AUTOSAR XML (schema 00053)
package /Application
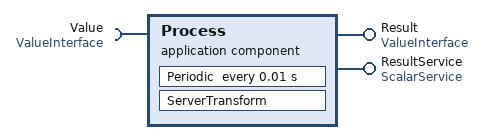
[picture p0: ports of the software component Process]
  application sw component type Process
    require port Value: nonqueued-receiver-com-spec{data-element=Value, init-value=7}, required-interface=ValueInterface
    provide port Result: nonqueued-sender-com-spec{data-element=Value, init-value=2}, provided-interface=ValueInterface
    provide port ResultService: server-com-spec{operation=Transform, queue-length=1}, provided-interface=ScalarService
    behavior Behavior: data-type-mapping=ApplicationTypes
      timing event Periodic10ms: start-on-event=Periodic, period=0.01
      operation invoked event InvokeTransform: start-on-event=ServerTransform, operation=ResultService.Transform
      runnable Periodic: symbol=Process_Periodic
        data-receive-point-by-arguments:
          access RValue: accessed-variable=Value.Value
        data-send-points:
          access PResult: accessed-variable=Result.Value
      runnable ServerTransform: symbol=Process_Transform
